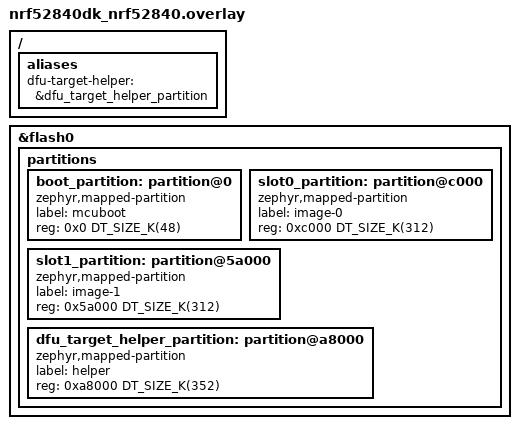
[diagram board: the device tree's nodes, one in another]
/*
 * Copyright (c) 2026 Nordic Semiconductor ASA
 *
 * SPDX-License-Identifier: LicenseRef-Nordic-5-Clause
 */

/delete-node/ &boot_partition;
/delete-node/ &slot0_partition;
/delete-node/ &slot1_partition;
/delete-node/ &storage_partition;

&flash0 {
	partitions {
		ranges;
		#address-cells = <1>;
		#size-cells = <1>;

		boot_partition: partition@0 {
			compatible = "zephyr,mapped-partition";
			label = "mcuboot";
			reg = <0x0 DT_SIZE_K(48)>;
		};

		slot0_partition: partition@c000 {
			compatible = "zephyr,mapped-partition";
			label = "image-0";
			reg = <0xc000 DT_SIZE_K(312)>;
		};

		slot1_partition: partition@5a000 {
			compatible = "zephyr,mapped-partition";
			label = "image-1";
			reg = <0x5a000 DT_SIZE_K(312)>;
		};

		dfu_target_helper_partition: partition@a8000 {
			compatible = "zephyr,mapped-partition";
			label = "helper";
			reg = <0xa8000 DT_SIZE_K(352)>;
		};
	};
};

/ {
	aliases {
		dfu-target-helper = &dfu_target_helper_partition;
	};
};
